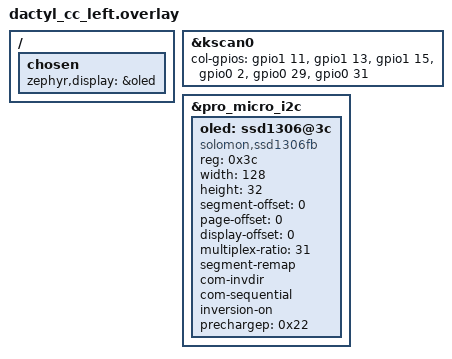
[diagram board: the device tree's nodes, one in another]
#include "dactyl_cc.dtsi"

/ {
    chosen {
        zephyr,display = &oled;
    };
};

&kscan0 {
    col-gpios
        = <&gpio1 11 GPIO_ACTIVE_HIGH> // col0 in the schematic
        , <&gpio1 13 GPIO_ACTIVE_HIGH> // col1 in the schematic
        , <&gpio1 15 GPIO_ACTIVE_HIGH> // col2 in the schematic
        , <&gpio0  2 GPIO_ACTIVE_HIGH> // col3 in the schematic
        , <&gpio0 29 GPIO_ACTIVE_HIGH> // col4 in the schematic
        , <&gpio0 31 GPIO_ACTIVE_HIGH> // col5 in the schematic
        ;
};

&pro_micro_i2c {
    status = "okay";

    oled: ssd1306@3c {
        compatible = "solomon,ssd1306fb";
        reg = <0x3c>;
        width = <128>;
        height = <32>;
        segment-offset = <0>;
        page-offset = <0>;
        display-offset = <0>;
        multiplex-ratio = <31>;
        segment-remap;
        com-invdir;
        com-sequential;
        inversion-on;
        prechargep = <0x22>;
    };
};
